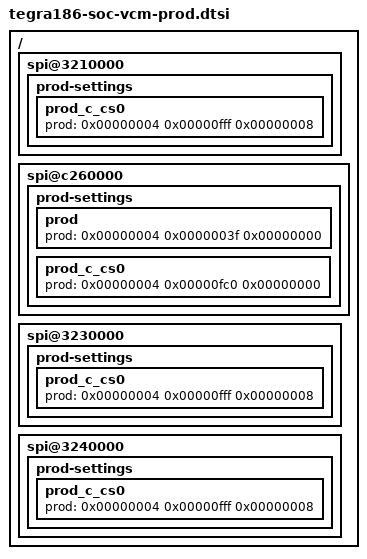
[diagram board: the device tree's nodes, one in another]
/*
 * T186 VCM package specific Prod configuration.
 *
 * Copyright (c) 2016, NVIDIA CORPORATION.  All rights reserved.
 *
 * This program is free software; you can redistribute it and/or modify
 * it under the terms of the GNU General Public License as published by
 * the Free Software Foundation; version 2 of the License.
 *
 */

/ {
	spi@3210000 {
		prod-settings {

			prod_c_cs0 {
				prod = <
					0x00000004 0x00000fff 0x00000008>;
			};
		};
	};

	spi@c260000 {
		prod-settings {

			prod {
				prod = <
					0x00000004 0x0000003f 0x00000000>;
			};
			prod_c_cs0 {
				prod = <
					0x00000004 0x00000fc0 0x00000000>;
			};
		};
	};

	spi@3230000 {
		prod-settings {

			prod_c_cs0 {
				prod = <
					0x00000004 0x00000fff 0x00000008>;
			};
		};
	};

	spi@3240000 {
		prod-settings {

			prod_c_cs0 {
				prod = <
					0x00000004 0x00000fff 0x00000008>;
			};
		};
	};
};
